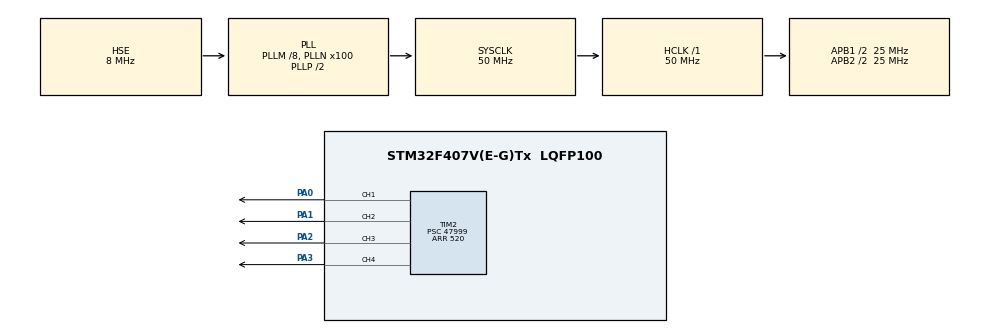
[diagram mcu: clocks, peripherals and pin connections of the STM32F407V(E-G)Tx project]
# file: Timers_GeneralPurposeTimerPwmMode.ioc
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Mcu.Family=STM32F4
Mcu.Name=STM32F407V(E-G)Tx
Mcu.Package=LQFP100
NVIC.PriorityGroup=NVIC_PRIORITYGROUP_0
PA0-WKUP.Signal=S_TIM2_CH1_ETR
PA1.Signal=S_TIM2_CH2
PA10.GPIO_Label=OTG_FS_ID
PA10.GPIO_Mode=GPIO_MODE_AF_PP
PA10.GPIO_PuPd=GPIO_NOPULL
PA10.GPIO_Speed=GPIO_SPEED_FREQ_LOW
PA10.Signal=USB_OTG_FS_ID
PA11.GPIO_Label=OTG_FS_DM
PA11.GPIO_Mode=GPIO_MODE_AF_PP
PA11.GPIO_PuPd=GPIO_NOPULL
PA11.GPIO_Speed=GPIO_SPEED_FREQ_LOW
PA11.Signal=USB_OTG_FS_DM
PA12.GPIO_Label=OTG_FS_DP
PA12.GPIO_Mode=GPIO_MODE_AF_PP
PA12.GPIO_PuPd=GPIO_NOPULL
PA12.GPIO_Speed=GPIO_SPEED_FREQ_LOW
PA12.Signal=USB_OTG_FS_DP
PA13.GPIO_Label=SWDIO
PA13.Signal=SYS_JTMS-SWDIO
PA14.GPIO_Label=SWCLK
PA14.Signal=SYS_JTCK-SWCLK
PA2.Signal=S_TIM2_CH3
PA3.Signal=S_TIM2_CH4
PA4.GPIO_Label=I2S3_WS [CS43L22_LRCK]
PA4.GPIO_Mode=GPIO_MODE_AF_PP
PA4.GPIO_PuPd=GPIO_NOPULL
PA4.GPIO_Speed=GPIO_SPEED_FREQ_LOW
PA4.Signal=I2S3_WS
PA5.GPIO_Label=SPI1_SCK [LIS302DL_SCL/SPC]
PA5.GPIO_Mode=GPIO_MODE_AF_PP
PA5.GPIO_PuPd=GPIO_NOPULL
PA5.GPIO_Speed=GPIO_SPEED_FREQ_LOW
PA5.Signal=SPI1_SCK
PA6.GPIO_Label=SPI1_MISO [LIS302DL_SDO]
PA6.GPIO_Mode=GPIO_MODE_AF_PP
PA6.GPIO_PuPd=GPIO_NOPULL
PA6.GPIO_Speed=GPIO_SPEED_FREQ_LOW
PA6.Signal=SPI1_MISO
PA7.GPIO_Label=SPI1_MOSI [LIS302DL_SDA/SDI/SDO]
PA7.GPIO_Mode=GPIO_MODE_AF_PP
PA7.GPIO_PuPd=GPIO_NOPULL
PA7.GPIO_Speed=GPIO_SPEED_FREQ_LOW
PA7.Signal=SPI1_MOSI
PA9.GPIO_Label=VBUS_FS
PA9.GPIO_Mode=GPIO_MODE_INPUT
PA9.GPIO_PuPd=GPIO_NOPULL
PA9.Signal=USB_OTG_FS_VBUS
PB10.GPIO_Label=CLK_IN [MP45DT02_CLK]
PB10.GPIO_Mode=GPIO_MODE_AF_PP
PB10.GPIO_PuPd=GPIO_NOPULL
PB10.GPIO_Speed=GPIO_SPEED_FREQ_LOW
PB10.Signal=I2S2_CK
PB3.GPIO_Label=SWO
PB3.Signal=SYS_JTDO-SWO
PB6.GPIO_Label=Audio_SCL [CS43L22_SCL]
PB6.GPIO_Mode=GPIO_MODE_AF_OD
PB6.GPIO_PuPd=GPIO_NOPULL
PB6.GPIO_Speed=GPIO_SPEED_FREQ_LOW
PB6.Signal=I2C1_SCL
PB9.GPIO_Label=Audio_SDA [CS43L22_SDA]
PB9.GPIO_Mode=GPIO_MODE_AF_OD
PB9.GPIO_PuPd=GPIO_NOPULL
PB9.GPIO_Speed=GPIO_SPEED_FREQ_LOW
PB9.Signal=I2C1_SDA
PC10.GPIO_Label=I2S3_SCK [CS43L22_SCLK]
PC10.GPIO_Mode=GPIO_MODE_AF_PP
PC10.GPIO_PuPd=GPIO_NOPULL
PC10.GPIO_Speed=GPIO_SPEED_FREQ_LOW
PC10.Signal=I2S3_CK
PC12.GPIO_Label=I2S3_SD [CS43L22_SDIN]
PC12.GPIO_Mode=GPIO_MODE_AF_PP
PC12.GPIO_PuPd=GPIO_NOPULL
PC12.GPIO_Speed=GPIO_SPEED_FREQ_LOW
PC12.Signal=I2S3_SD
PC14-OSC32_IN.GPIO_Label=PC14-OSC32_IN
PC14-OSC32_IN.Signal=RCC_OSC32_IN
PC15-OSC32_OUT.GPIO_Label=PC15-OSC32_OUT
PC15-OSC32_OUT.Signal=RCC_OSC32_OUT
PC3.GPIO_Label=PDM_OUT [MP45DT02_DOUT]
PC3.GPIO_Mode=GPIO_MODE_AF_PP
PC3.GPIO_PuPd=GPIO_NOPULL
PC3.GPIO_Speed=GPIO_SPEED_FREQ_LOW
PC3.Signal=I2S2_SD
PC7.GPIO_Label=I2S3_MCK [CS43L22_MCLK]
PC7.GPIO_Mode=GPIO_MODE_AF_PP
PC7.GPIO_PuPd=GPIO_NOPULL
PC7.GPIO_Speed=GPIO_SPEED_FREQ_LOW
PC7.Signal=I2S3_MCK
PH0-OSC_IN.GPIO_Label=PH0-OSC_IN
PH0-OSC_IN.Mode=HSE-External-Oscillator
PH0-OSC_IN.Signal=RCC_OSC_IN
PH1-OSC_OUT.GPIO_Label=PH1-OSC_OUT
PH1-OSC_OUT.Mode=HSE-External-Oscillator
PH1-OSC_OUT.Signal=RCC_OSC_OUT
ProjectManager.HeapSize=0x200
ProjectManager.StackSize=0x400
ProjectManager.TargetToolchain=STM32CubeIDE
RCC.48MHZClocksFreq_Value=14285714.285714285
RCC.AHBFreq_Value=50000000
RCC.APB1CLKDivider=RCC_HCLK_DIV2
RCC.APB1Freq_Value=25000000
RCC.APB1TimFreq_Value=50000000
RCC.APB2CLKDivider=RCC_HCLK_DIV2
RCC.APB2Freq_Value=25000000
RCC.APB2TimFreq_Value=50000000
RCC.CortexFreq_Value=50000000
RCC.HCLKFreq_Value=50000000
RCC.HSE_VALUE=8000000
RCC.HSI_VALUE=16000000
RCC.LSE_VALUE=32768
RCC.PLLM=8
RCC.PLLN=100
RCC.PLLQ=7
RCC.PLLSourceVirtual=RCC_PLLSOURCE_HSE
RCC.SYSCLKFreq_VALUE=50000000
RCC.SYSCLKSource=RCC_SYSCLKSOURCE_PLLCLK
RCC.VCOOutputFreq_Value=100000000
SH.S_TIM2_CH1_ETR.0=TIM2_CH1,PWM Generation1 CH1
SH.S_TIM2_CH2.0=TIM2_CH2,PWM Generation2 CH2
SH.S_TIM2_CH3.0=TIM2_CH3,PWM Generation3 CH3
SH.S_TIM2_CH4.0=TIM2_CH4,PWM Generation4 CH4
TIM2.Channel-PWM\ Generation1\ CH1=TIM_CHANNEL_1
TIM2.Channel-PWM\ Generation2\ CH2=TIM_CHANNEL_2
TIM2.Channel-PWM\ Generation3\ CH3=TIM_CHANNEL_3
TIM2.Channel-PWM\ Generation4\ CH4=TIM_CHANNEL_4
TIM2.Period=520
TIM2.Prescaler=47999
TIM2.Pulse-PWM\ Generation1\ CH1=130
TIM2.Pulse-PWM\ Generation2\ CH2=260
TIM2.Pulse-PWM\ Generation3\ CH3=390
TIM2.Pulse-PWM\ Generation4\ CH4=520
board=STM32F407G-DISC1

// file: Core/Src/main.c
/* USER CODE BEGIN Header */
/**
  ******************************************************************************
  * @file           : main.c
  * @brief          : Main program body
  ******************************************************************************
  * @attention
  *
  * <h2><center>&copy; Copyright (c) 2020 STMicroelectronics.
  * All rights reserved.</center></h2>
  *
  * This software component is licensed by ST under BSD 3-Clause license,
  * the "License"; You may not use this file except in compliance with the
  * License. You may obtain a copy of the License at:
  *                        opensource.org/licenses/BSD-3-Clause
  *
  ******************************************************************************
  */
/* USER CODE END Header */
#include "main.h"

TIM_HandleTypeDef htim2;

void SystemClock_Config(void);
static void MX_GPIO_Init(void);
static void MX_TIM2_Init(void);

int main(void)
{

  /* MCU Configuration--------------------------------------------------------*/

  /* Reset of all peripherals, Initializes the Flash interface and the Systick. */
  HAL_Init();

  /* Configure the system clock */
  SystemClock_Config();

  /* Initialize all configured peripherals */
  MX_GPIO_Init();
  MX_TIM2_Init();
  /* USER CODE BEGIN 2 */
HAL_TIM_PWM_Start(&htim2, TIM_CHANNEL_1);
HAL_TIM_PWM_Start(&htim2, TIM_CHANNEL_2);
HAL_TIM_PWM_Start(&htim2, TIM_CHANNEL_3);
HAL_TIM_PWM_Start(&htim2, TIM_CHANNEL_4);
__HAL_TIM_GET_AUTORELOAD(&htim2);
  /* USER CODE END 2 */

  /* Infinite loop */
  /* USER CODE BEGIN WHILE */
  while (1)
  {
	  HAL_Delay(5000);
	  __HAL_TIM_SET_COMPARE(&htim2, TIM_CHANNEL_1, 520);
	  __HAL_TIM_SET_COMPARE(&htim2, TIM_CHANNEL_2, 390);
	  __HAL_TIM_SET_COMPARE(&htim2, TIM_CHANNEL_3, 260);
	  __HAL_TIM_SET_COMPARE(&htim2, TIM_CHANNEL_4, 130);
    /* USER CODE END WHILE */

  }
}

void SystemClock_Config(void)
{
  RCC_OscInitTypeDef RCC_OscInitStruct = {0};
  RCC_ClkInitTypeDef RCC_ClkInitStruct = {0};

  /** Configure the main internal regulator output voltage
  */
  __HAL_RCC_PWR_CLK_ENABLE();
  __HAL_PWR_VOLTAGESCALING_CONFIG(PWR_REGULATOR_VOLTAGE_SCALE1);
  /** Initializes the RCC Oscillators according to the specified parameters
  * in the RCC_OscInitTypeDef structure.
  */
  RCC_OscInitStruct.OscillatorType = RCC_OSCILLATORTYPE_HSE;
  RCC_OscInitStruct.HSEState = RCC_HSE_ON;
  RCC_OscInitStruct.PLL.PLLState = RCC_PLL_ON;
  RCC_OscInitStruct.PLL.PLLSource = RCC_PLLSOURCE_HSE;
  RCC_OscInitStruct.PLL.PLLM = 8;
  RCC_OscInitStruct.PLL.PLLN = 100;
  RCC_OscInitStruct.PLL.PLLP = RCC_PLLP_DIV2;
  RCC_OscInitStruct.PLL.PLLQ = 7;
  if (HAL_RCC_OscConfig(&RCC_OscInitStruct) != HAL_OK)
  {
    Error_Handler();
  }
  /** Initializes the CPU, AHB and APB buses clocks
  */
  RCC_ClkInitStruct.ClockType = RCC_CLOCKTYPE_HCLK|RCC_CLOCKTYPE_SYSCLK
                              |RCC_CLOCKTYPE_PCLK1|RCC_CLOCKTYPE_PCLK2;
  RCC_ClkInitStruct.SYSCLKSource = RCC_SYSCLKSOURCE_PLLCLK;
  RCC_ClkInitStruct.AHBCLKDivider = RCC_SYSCLK_DIV1;
  RCC_ClkInitStruct.APB1CLKDivider = RCC_HCLK_DIV2;
  RCC_ClkInitStruct.APB2CLKDivider = RCC_HCLK_DIV2;

  if (HAL_RCC_ClockConfig(&RCC_ClkInitStruct, FLASH_LATENCY_1) != HAL_OK)
  {
    Error_Handler();
  }
}

static void MX_TIM2_Init(void)
{

  TIM_MasterConfigTypeDef sMasterConfig = {0};
  TIM_OC_InitTypeDef sConfigOC = {0};

  htim2.Instance = TIM2;
  htim2.Init.Prescaler = 47999;
  htim2.Init.CounterMode = TIM_COUNTERMODE_UP;
  htim2.Init.Period = 520;
  htim2.Init.ClockDivision = TIM_CLOCKDIVISION_DIV1;
  htim2.Init.AutoReloadPreload = TIM_AUTORELOAD_PRELOAD_DISABLE;
  if (HAL_TIM_PWM_Init(&htim2) != HAL_OK)
  {
    Error_Handler();
  }
  sMasterConfig.MasterOutputTrigger = TIM_TRGO_RESET;
  sMasterConfig.MasterSlaveMode = TIM_MASTERSLAVEMODE_DISABLE;
  if (HAL_TIMEx_MasterConfigSynchronization(&htim2, &sMasterConfig) != HAL_OK)
  {
    Error_Handler();
  }
  sConfigOC.OCMode = TIM_OCMODE_PWM1;
  sConfigOC.Pulse = 130;
  sConfigOC.OCPolarity = TIM_OCPOLARITY_HIGH;
  sConfigOC.OCFastMode = TIM_OCFAST_DISABLE;
  if (HAL_TIM_PWM_ConfigChannel(&htim2, &sConfigOC, TIM_CHANNEL_1) != HAL_OK)
  {
    Error_Handler();
  }
  sConfigOC.Pulse = 260;
  if (HAL_TIM_PWM_ConfigChannel(&htim2, &sConfigOC, TIM_CHANNEL_2) != HAL_OK)
  {
    Error_Handler();
  }
  sConfigOC.Pulse = 390;
  if (HAL_TIM_PWM_ConfigChannel(&htim2, &sConfigOC, TIM_CHANNEL_3) != HAL_OK)
  {
    Error_Handler();
  }
  sConfigOC.Pulse = 520;
  if (HAL_TIM_PWM_ConfigChannel(&htim2, &sConfigOC, TIM_CHANNEL_4) != HAL_OK)
  {
    Error_Handler();
  }
  HAL_TIM_MspPostInit(&htim2);

}

static void MX_GPIO_Init(void)
{
  GPIO_InitTypeDef GPIO_InitStruct = {0};

  /* GPIO Ports Clock Enable */
  __HAL_RCC_GPIOC_CLK_ENABLE();
  __HAL_RCC_GPIOH_CLK_ENABLE();
  __HAL_RCC_GPIOA_CLK_ENABLE();
  __HAL_RCC_GPIOB_CLK_ENABLE();

  /*Configure GPIO pin : PDM_OUT_Pin */
  GPIO_InitStruct.Pin = PDM_OUT_Pin;
  GPIO_InitStruct.Mode = GPIO_MODE_AF_PP;
  GPIO_InitStruct.Pull = GPIO_NOPULL;
  GPIO_InitStruct.Speed = GPIO_SPEED_FREQ_LOW;
  GPIO_InitStruct.Alternate = GPIO_AF5_SPI2;
  HAL_GPIO_Init(PDM_OUT_GPIO_Port, &GPIO_InitStruct);

  /*Configure GPIO pin : I2S3_WS_Pin */
  GPIO_InitStruct.Pin = I2S3_WS_Pin;
  GPIO_InitStruct.Mode = GPIO_MODE_AF_PP;
  GPIO_InitStruct.Pull = GPIO_NOPULL;
  GPIO_InitStruct.Speed = GPIO_SPEED_FREQ_LOW;
  GPIO_InitStruct.Alternate = GPIO_AF6_SPI3;
  HAL_GPIO_Init(I2S3_WS_GPIO_Port, &GPIO_InitStruct);

  /*Configure GPIO pins : SPI1_SCK_Pin SPI1_MISO_Pin SPI1_MOSI_Pin */
  GPIO_InitStruct.Pin = SPI1_SCK_Pin|SPI1_MISO_Pin|SPI1_MOSI_Pin;
  GPIO_InitStruct.Mode = GPIO_MODE_AF_PP;
  GPIO_InitStruct.Pull = GPIO_NOPULL;
  GPIO_InitStruct.Speed = GPIO_SPEED_FREQ_LOW;
  GPIO_InitStruct.Alternate = GPIO_AF5_SPI1;
  HAL_GPIO_Init(GPIOA, &GPIO_InitStruct);

  /*Configure GPIO pin : CLK_IN_Pin */
  GPIO_InitStruct.Pin = CLK_IN_Pin;
  GPIO_InitStruct.Mode = GPIO_MODE_AF_PP;
  GPIO_InitStruct.Pull = GPIO_NOPULL;
  GPIO_InitStruct.Speed = GPIO_SPEED_FREQ_LOW;
  GPIO_InitStruct.Alternate = GPIO_AF5_SPI2;
  HAL_GPIO_Init(CLK_IN_GPIO_Port, &GPIO_InitStruct);

  /*Configure GPIO pins : I2S3_MCK_Pin I2S3_SCK_Pin I2S3_SD_Pin */
  GPIO_InitStruct.Pin = I2S3_MCK_Pin|I2S3_SCK_Pin|I2S3_SD_Pin;
  GPIO_InitStruct.Mode = GPIO_MODE_AF_PP;
  GPIO_InitStruct.Pull = GPIO_NOPULL;
  GPIO_InitStruct.Speed = GPIO_SPEED_FREQ_LOW;
  GPIO_InitStruct.Alternate = GPIO_AF6_SPI3;
  HAL_GPIO_Init(GPIOC, &GPIO_InitStruct);

  /*Configure GPIO pin : VBUS_FS_Pin */
  GPIO_InitStruct.Pin = VBUS_FS_Pin;
  GPIO_InitStruct.Mode = GPIO_MODE_INPUT;
  GPIO_InitStruct.Pull = GPIO_NOPULL;
  HAL_GPIO_Init(VBUS_FS_GPIO_Port, &GPIO_InitStruct);

  /*Configure GPIO pins : OTG_FS_ID_Pin OTG_FS_DM_Pin OTG_FS_DP_Pin */
  GPIO_InitStruct.Pin = OTG_FS_ID_Pin|OTG_FS_DM_Pin|OTG_FS_DP_Pin;
  GPIO_InitStruct.Mode = GPIO_MODE_AF_PP;
  GPIO_InitStruct.Pull = GPIO_NOPULL;
  GPIO_InitStruct.Speed = GPIO_SPEED_FREQ_LOW;
  GPIO_InitStruct.Alternate = GPIO_AF10_OTG_FS;
  HAL_GPIO_Init(GPIOA, &GPIO_InitStruct);

  /*Configure GPIO pins : Audio_SCL_Pin Audio_SDA_Pin */
  GPIO_InitStruct.Pin = Audio_SCL_Pin|Audio_SDA_Pin;
  GPIO_InitStruct.Mode = GPIO_MODE_AF_OD;
  GPIO_InitStruct.Pull = GPIO_PULLUP;
  GPIO_InitStruct.Speed = GPIO_SPEED_FREQ_LOW;
  GPIO_InitStruct.Alternate = GPIO_AF4_I2C1;
  HAL_GPIO_Init(GPIOB, &GPIO_InitStruct);

}

void Error_Handler(void)
{
}

/************************ (C) COPYRIGHT STMicroelectronics *****END OF FILE****/
